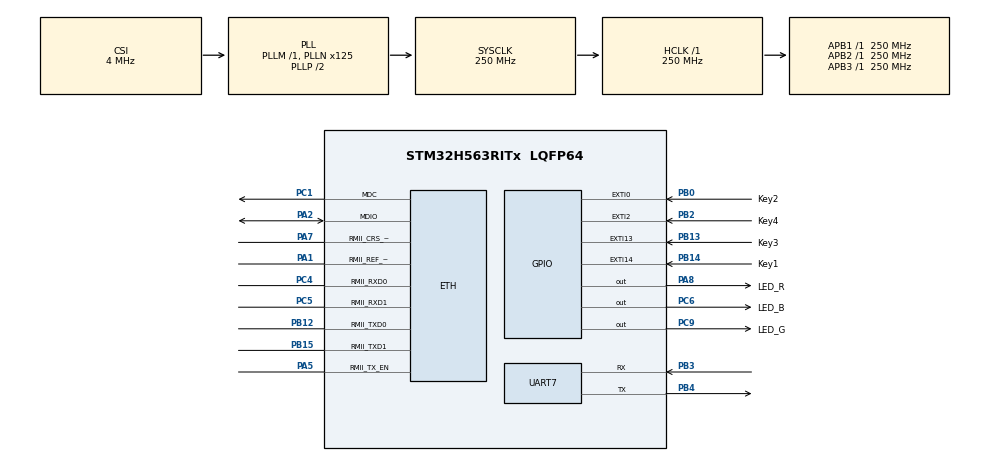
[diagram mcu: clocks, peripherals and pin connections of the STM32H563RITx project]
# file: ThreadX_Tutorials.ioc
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BOOTPATH.BootPathName=LEGACY
BOOTPATH.UserSelectedBootPath=LEGACY
CORTEX_M33_NS.Number-Cortex_Memory_Protection_Unit_Region0_OTP_RO_AREAS_Settings=MPU_REGION_NUMBER0
CORTEX_M33_NS.default_mode_Activation=1
CORTEX_M33_NS.userName=CORTEX_M33
ETH.MediaInterface=HAL_ETH_RMII_MODE
Mcu.Family=STM32H5
Mcu.Name=STM32H563RITx
Mcu.Package=LQFP64
NETXDUO.ETH_ON=1
NETXDUO.LAN_8742=1
NETXDUO.NX_APP_IP_INSTANCE_THREAD_SIZE=2048
NETXDUO.NX_APP_MEM_POOL_SIZE=102400
NETXDUO.NX_APP_PACKET_POOL_SIZE=50
NETXDUO.NX_APP_THREAD_STACK_SIZE=2048
NETXDUO.NetXDuo_Generate_Init_Code=true
NETXDUO.NetXDuo_Static_IP_address=192.168.10.2
NVIC.ETH_IRQn=true\:7\:0\:true\:false\:true\:false\:true\:true\:true
NVIC.EXTI0_IRQn=true\:5\:0\:true\:false\:true\:false\:true\:true\:true
NVIC.EXTI13_IRQn=true\:5\:0\:true\:false\:true\:false\:true\:true\:true
NVIC.EXTI14_IRQn=true\:5\:0\:true\:false\:true\:false\:true\:true\:true
NVIC.EXTI2_IRQn=true\:5\:0\:true\:false\:true\:false\:true\:true\:true
NVIC.PriorityGroup=NVIC_PRIORITYGROUP_4
NVIC.TIM6_IRQn=true\:15\:0\:false\:false\:true\:false\:false\:true\:true
NVIC.TimeBase=TIM6_IRQn
NVIC.TimeBaseIP=TIM6
NetXDuo.BSP.number=1
NetXDuo0.BSP.STBoard=false
NetXDuo0.BSP.api=BSP_COMPONENT_DRIVER
NetXDuo0.BSP.component=lan8742
NetXDuo0.BSP.instance=lan8742
NetXDuo0.BSP.name=LAN_Component
NetXDuo0.BSP.semaphore=SEMA_lan8742
NetXDuo0.BSP.solution=lan8742
PA1.GPIO_Speed_Default_HIGH=GPIO_SPEED_FREQ_VERY_HIGH
PA1.Mode=RMII
PA1.Signal=ETH_RMII_REF_CLK
PA2.GPIO_Speed_Default_HIGH=GPIO_SPEED_FREQ_VERY_HIGH
PA2.Mode=RMII
PA2.Signal=ETH_MDIO
PA5.GPIO_Speed_Default_HIGH=GPIO_SPEED_FREQ_VERY_HIGH
PA5.Mode=RMII
PA5.Signal=ETH_RMII_TX_EN
PA7.GPIO_Speed_Default_HIGH=GPIO_SPEED_FREQ_VERY_HIGH
PA7.Mode=RMII
PA7.Signal=ETH_RMII_CRS_DV
PA8.GPIO_Label=LED_R
PA8.PinState=GPIO_PIN_SET
PA8.Signal=GPIO_Output
PB0.GPIO_Label=Key2
PB0.GPIO_ModeDefaultEXTI=GPIO_MODE_IT_FALLING
PB0.Signal=GPXTI0
PB12.GPIO_Speed_Default_HIGH=GPIO_SPEED_FREQ_VERY_HIGH
PB12.Mode=RMII
PB12.Signal=ETH_RMII_TXD0
PB13.GPIO_Label=Key3
PB13.GPIO_ModeDefaultEXTI=GPIO_MODE_IT_FALLING
PB13.Signal=GPXTI13
PB14.GPIO_Label=Key1
PB14.GPIO_ModeDefaultEXTI=GPIO_MODE_IT_FALLING
PB14.Signal=GPXTI14
PB15.GPIO_Speed_Default_HIGH=GPIO_SPEED_FREQ_VERY_HIGH
PB15.Mode=RMII
PB15.Signal=ETH_RMII_TXD1
PB2.GPIO_Label=Key4
PB2.GPIO_ModeDefaultEXTI=GPIO_MODE_IT_FALLING
PB2.Signal=GPXTI2
PB3(JTDO/TRACESWO).Mode=Asynchronous
PB3(JTDO/TRACESWO).Signal=UART7_RX
PB4(NJTRST).Mode=Asynchronous
PB4(NJTRST).Signal=UART7_TX
PC1.GPIO_Speed_Default_HIGH=GPIO_SPEED_FREQ_VERY_HIGH
PC1.Mode=RMII
PC1.Signal=ETH_MDC
PC4.GPIO_Speed_Default_HIGH=GPIO_SPEED_FREQ_VERY_HIGH
PC4.Mode=RMII
PC4.Signal=ETH_RMII_RXD0
PC5.GPIO_Speed_Default_HIGH=GPIO_SPEED_FREQ_VERY_HIGH
PC5.Mode=RMII
PC5.Signal=ETH_RMII_RXD1
PC6.GPIO_Label=LED_B
PC6.PinState=GPIO_PIN_SET
PC6.Signal=GPIO_Output
PC9.GPIO_Label=LED_G
PC9.PinState=GPIO_PIN_SET
PC9.Signal=GPIO_Output
PH0-OSC_IN(PH0).Mode=HSE-External-Clock-Source
PH0-OSC_IN(PH0).Signal=RCC_OSC_IN
ProjectManager.HeapSize=0x200
ProjectManager.StackSize=0x400
ProjectManager.TargetToolchain=STM32CubeIDE
RCC.ADCFreq_Value=250000000
RCC.AHBFreq_Value=250000000
RCC.APB1Freq_Value=250000000
RCC.APB1TimFreq_Value=250000000
RCC.APB2Freq_Value=250000000
RCC.APB2TimFreq_Value=250000000
RCC.APB3Freq_Value=250000000
RCC.CSI_VALUE=4000000
RCC.CortexFreq_Value=250000000
RCC.EPOD_VALUE=4000000
RCC.HCLKFreq_Value=250000000
RCC.HSE_VALUE=25000000
RCC.HSI48_VALUE=48000000
RCC.HSI_VALUE=64000000
RCC.LSE_VALUE=32768
RCC.LSIRC_VALUE=32000
RCC.PLL2FRACN=0
RCC.PLL3FRACN=0
RCC.PLLFRACN=0
RCC.PLLN=125
RCC.SYSCLKFreq_VALUE=250000000
RCC.SYSCLKSource=RCC_SYSCLKSOURCE_PLLCLK
RCC.USBFreq_Value=48000000
RCC.VCOOutputFreq_Value=500000000
THREADX.TX_APP_GENERATE_INIT_CODE=true
THREADX.TX_APP_MEM_POOL_SIZE=16384
VP_BOOTPATH_VS_BOOTPATH.Mode=BP_Activate
VP_CORTEX_M33_NS_VS_Hclk.Mode=Hclk_Mode
VP_ICACHE_VS_ICACHE.Mode=DirectMappedCache
VP_MEMORYMAP_VS_MEMORYMAP.Mode=CurAppReg
VP_NETXDUO_VS_EthernetOoPhyOoInterface.Mode=LAN8742_Phy_Interface
VP_NETXDUO_VS_NXOoCore.Mode=NX_Core
VP_NETXDUO_VS_NetworkOoInterface.Mode=Ethernet_Interface
VP_PWR_VS_LPOM.Mode=PowerOptimisation
VP_PWR_VS_SECSignals.Mode=Security/Privilege
VP_SYS_VS_tim6.Mode=TIM6
VP_THREADX_VS_RTOSJjThreadXJjCoreJjDefault.Mode=Core_Default
board=custom

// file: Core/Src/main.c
/* USER CODE BEGIN Header */
/**
  ******************************************************************************
  * @file           : main.c
  * @brief          : Main program body
  ******************************************************************************
  * @attention
  *
  * Copyright (c) 2026 STMicroelectronics.
  * All rights reserved.
  *
  * This software is licensed under terms that can be found in the LICENSE file
  * in the root directory of this software component.
  * If no LICENSE file comes with this software, it is provided AS-IS.
  *
  ******************************************************************************
  */
/* USER CODE END Header */
#include "app_threadx.h"
#include "main.h"
#include "eth.h"
#include "icache.h"
#include "usart.h"
#include "gpio.h"

/* USER CODE BEGIN Includes */
#include <stdio.h>
/* USER CODE END Includes */

void SystemClock_Config(void);
static void MPU_Config(void);

int main(void)
{

  /* MCU Configuration--------------------------------------------------------*/

  /* MPU Configuration--------------------------------------------------------*/
  MPU_Config();

  /* Reset of all peripherals, Initializes the Flash interface and the Systick. */
  HAL_Init();

  /* Configure the system clock */
  SystemClock_Config();

  /* Initialize all configured peripherals */
  MX_GPIO_Init();
  MX_ICACHE_Init();
  MX_UART7_Init();
  MX_ETH_Init();

  MX_ThreadX_Init();

  /* We should never get here as control is now taken by the scheduler */

  /* Infinite loop */
  /* USER CODE BEGIN WHILE */
  while (1)
  {
	HAL_GPIO_TogglePin(LED_B_GPIO_Port, LED_B_Pin);
	printf("tick %lu\r\n", HAL_GetTick());
	HAL_Delay(500);
    /* USER CODE END WHILE */

  }
}

void SystemClock_Config(void)
{
  RCC_OscInitTypeDef RCC_OscInitStruct = {0};
  RCC_ClkInitTypeDef RCC_ClkInitStruct = {0};

  /** Configure the main internal regulator output voltage
  */
  __HAL_PWR_VOLTAGESCALING_CONFIG(PWR_REGULATOR_VOLTAGE_SCALE0);

  while(!__HAL_PWR_GET_FLAG(PWR_FLAG_VOSRDY)) {}

  /** Initializes the RCC Oscillators according to the specified parameters
  * in the RCC_OscInitTypeDef structure.
  */
  RCC_OscInitStruct.OscillatorType = RCC_OSCILLATORTYPE_CSI;
  RCC_OscInitStruct.CSIState = RCC_CSI_ON;
  RCC_OscInitStruct.CSICalibrationValue = RCC_CSICALIBRATION_DEFAULT;
  RCC_OscInitStruct.PLL.PLLState = RCC_PLL_ON;
  RCC_OscInitStruct.PLL.PLLSource = RCC_PLL1_SOURCE_CSI;
  RCC_OscInitStruct.PLL.PLLM = 1;
  RCC_OscInitStruct.PLL.PLLN = 125;
  RCC_OscInitStruct.PLL.PLLP = 2;
  RCC_OscInitStruct.PLL.PLLQ = 2;
  RCC_OscInitStruct.PLL.PLLR = 2;
  RCC_OscInitStruct.PLL.PLLRGE = RCC_PLL1_VCIRANGE_2;
  RCC_OscInitStruct.PLL.PLLVCOSEL = RCC_PLL1_VCORANGE_WIDE;
  RCC_OscInitStruct.PLL.PLLFRACN = 0;
  if (HAL_RCC_OscConfig(&RCC_OscInitStruct) != HAL_OK)
  {
    Error_Handler();
  }

  /** Initializes the CPU, AHB and APB buses clocks
  */
  RCC_ClkInitStruct.ClockType = RCC_CLOCKTYPE_HCLK|RCC_CLOCKTYPE_SYSCLK
                              |RCC_CLOCKTYPE_PCLK1|RCC_CLOCKTYPE_PCLK2
                              |RCC_CLOCKTYPE_PCLK3;
  RCC_ClkInitStruct.SYSCLKSource = RCC_SYSCLKSOURCE_PLLCLK;
  RCC_ClkInitStruct.AHBCLKDivider = RCC_SYSCLK_DIV1;
  RCC_ClkInitStruct.APB1CLKDivider = RCC_HCLK_DIV1;
  RCC_ClkInitStruct.APB2CLKDivider = RCC_HCLK_DIV1;
  RCC_ClkInitStruct.APB3CLKDivider = RCC_HCLK_DIV1;

  if (HAL_RCC_ClockConfig(&RCC_ClkInitStruct, FLASH_LATENCY_5) != HAL_OK)
  {
    Error_Handler();
  }

  /** Configure the programming delay
  */
  __HAL_FLASH_SET_PROGRAM_DELAY(FLASH_PROGRAMMING_DELAY_2);
}

 /* MPU Configuration */

void MPU_Config(void)
{
  MPU_Region_InitTypeDef MPU_InitStruct = {0};
  MPU_Attributes_InitTypeDef MPU_AttributesInit = {0};

  /* Disables the MPU */
  HAL_MPU_Disable();

  /** Initializes and configures the Region 0 and the memory to be protected
  */
  MPU_InitStruct.Enable = MPU_REGION_ENABLE;
  MPU_InitStruct.Number = MPU_REGION_NUMBER0;
  MPU_InitStruct.BaseAddress = 0x08FFF000;
  MPU_InitStruct.LimitAddress = 0x08FFFFFF;
  MPU_InitStruct.AttributesIndex = MPU_ATTRIBUTES_NUMBER0;
  MPU_InitStruct.AccessPermission = MPU_REGION_ALL_RO;
  MPU_InitStruct.DisableExec = MPU_INSTRUCTION_ACCESS_DISABLE;
  MPU_InitStruct.IsShareable = MPU_ACCESS_NOT_SHAREABLE;

  HAL_MPU_ConfigRegion(&MPU_InitStruct);

  /** Initializes and configures the Attribute 0 and the memory to be protected
  */
  MPU_AttributesInit.Number = MPU_ATTRIBUTES_NUMBER0;
  MPU_AttributesInit.Attributes = INNER_OUTER(MPU_NOT_CACHEABLE);

  HAL_MPU_ConfigMemoryAttributes(&MPU_AttributesInit);
  /* Enables the MPU */
  HAL_MPU_Enable(MPU_PRIVILEGED_DEFAULT);

}

void HAL_TIM_PeriodElapsedCallback(TIM_HandleTypeDef *htim)
{
  if (htim->Instance == TIM6)
  {
    HAL_IncTick();
  }
}

void Error_Handler(void)
{
  __disable_irq();
  while (1)
  {
  }
}
